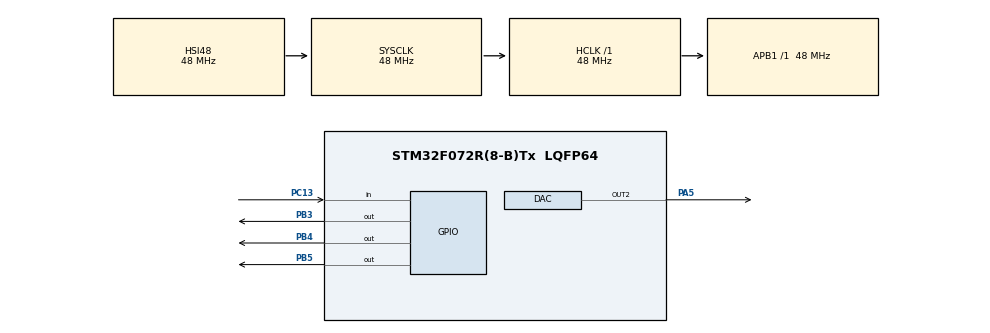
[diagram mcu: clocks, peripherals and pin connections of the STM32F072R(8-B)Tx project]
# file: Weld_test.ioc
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Mcu.Family=STM32F0
Mcu.Name=STM32F072R(8-B)Tx
Mcu.Package=LQFP64
NVIC.TIM6_DAC_IRQn=true\:0\:0\:false\:false\:true\:true\:true\:true
PA5.Signal=COMP_DAC2_group
PB3.Signal=GPIO_Output
PB4.Signal=GPIO_Output
PB5.Signal=GPIO_Output
PC13.Signal=GPIO_Input
ProjectManager.HeapSize=0x200
ProjectManager.StackSize=0x400
ProjectManager.TargetToolchain=STM32CubeIDE
RCC.AHBFreq_Value=48000000
RCC.APB1Freq_Value=48000000
RCC.APB1TimFreq_Value=48000000
RCC.HCLKFreq_Value=48000000
RCC.SYSCLKFreq_VALUE=48000000
RCC.SYSCLKSource=RCC_SYSCLKSOURCE_HSI48
SH.COMP_DAC2_group.0=DAC_OUT2,DAC_OUT2
TIM6.Period=99
TIM6.Prescaler=47
VP_TIM6_VS_ClockSourceINT.Mode=Enable_Timer
board=custom

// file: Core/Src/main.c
/* USER CODE BEGIN Header */
/**
  ******************************************************************************
  * @file           : main.c
  * @brief          : Main program body
  ******************************************************************************
  * @attention
  *
  * Copyright (c) 2026 STMicroelectronics.
  * All rights reserved.
  *
  * This software is licensed under terms that can be found in the LICENSE file
  * in the root directory of this software component.
  * If no LICENSE file comes with this software, it is provided AS-IS.
  *
  ******************************************************************************
  */
/* USER CODE END Header */
#include "main.h"

/* USER CODE BEGIN Includes */
#include "demo_wave.h"
/* USER CODE END Includes */

DAC_HandleTypeDef hdac;

TIM_HandleTypeDef htim6;

void SystemClock_Config(void);
static void MX_GPIO_Init(void);
static void MX_DAC_Init(void);
static void MX_TIM6_Init(void);

int main(void)
{

  /* MCU Configuration--------------------------------------------------------*/

  /* Reset of all peripherals, Initializes the Flash interface and the Systick. */
  HAL_Init();

  /* Configure the system clock */
  SystemClock_Config();

  /* Initialize all configured peripherals */
  MX_GPIO_Init();
  MX_DAC_Init();
  MX_TIM6_Init();
  /* USER CODE BEGIN 2 */
demo_init();
  /* USER CODE END 2 */

  /* Infinite loop */
  while (1)
  {

    /* USER CODE BEGIN 3 */
	  demo_poll();
  }
  /* USER CODE END 3 */
}

void SystemClock_Config(void)
{
  RCC_OscInitTypeDef RCC_OscInitStruct = {0};
  RCC_ClkInitTypeDef RCC_ClkInitStruct = {0};

  /** Initializes the RCC Oscillators according to the specified parameters
  * in the RCC_OscInitTypeDef structure.
  */
  RCC_OscInitStruct.OscillatorType = RCC_OSCILLATORTYPE_HSI48;
  RCC_OscInitStruct.HSI48State = RCC_HSI48_ON;
  RCC_OscInitStruct.PLL.PLLState = RCC_PLL_NONE;
  if (HAL_RCC_OscConfig(&RCC_OscInitStruct) != HAL_OK)
  {
    Error_Handler();
  }

  /** Initializes the CPU, AHB and APB buses clocks
  */
  RCC_ClkInitStruct.ClockType = RCC_CLOCKTYPE_HCLK|RCC_CLOCKTYPE_SYSCLK
                              |RCC_CLOCKTYPE_PCLK1;
  RCC_ClkInitStruct.SYSCLKSource = RCC_SYSCLKSOURCE_HSI48;
  RCC_ClkInitStruct.AHBCLKDivider = RCC_SYSCLK_DIV1;
  RCC_ClkInitStruct.APB1CLKDivider = RCC_HCLK_DIV1;

  if (HAL_RCC_ClockConfig(&RCC_ClkInitStruct, FLASH_LATENCY_1) != HAL_OK)
  {
    Error_Handler();
  }
}

static void MX_DAC_Init(void)
{

  DAC_ChannelConfTypeDef sConfig = {0};

  /** DAC Initialization
  */
  hdac.Instance = DAC;
  if (HAL_DAC_Init(&hdac) != HAL_OK)
  {
    Error_Handler();
  }

  /** DAC channel OUT2 config
  */
  sConfig.DAC_Trigger = DAC_TRIGGER_NONE;
  sConfig.DAC_OutputBuffer = DAC_OUTPUTBUFFER_ENABLE;
  if (HAL_DAC_ConfigChannel(&hdac, &sConfig, DAC_CHANNEL_2) != HAL_OK)
  {
    Error_Handler();
  }

}

static void MX_TIM6_Init(void)
{

  TIM_MasterConfigTypeDef sMasterConfig = {0};

  htim6.Instance = TIM6;
  htim6.Init.Prescaler = 47;
  htim6.Init.CounterMode = TIM_COUNTERMODE_UP;
  htim6.Init.Period = 99;
  htim6.Init.AutoReloadPreload = TIM_AUTORELOAD_PRELOAD_DISABLE;
  if (HAL_TIM_Base_Init(&htim6) != HAL_OK)
  {
    Error_Handler();
  }
  sMasterConfig.MasterOutputTrigger = TIM_TRGO_RESET;
  sMasterConfig.MasterSlaveMode = TIM_MASTERSLAVEMODE_DISABLE;
  if (HAL_TIMEx_MasterConfigSynchronization(&htim6, &sMasterConfig) != HAL_OK)
  {
    Error_Handler();
  }

}

static void MX_GPIO_Init(void)
{
  GPIO_InitTypeDef GPIO_InitStruct = {0};

  /* GPIO Ports Clock Enable */
  __HAL_RCC_GPIOC_CLK_ENABLE();
  __HAL_RCC_GPIOA_CLK_ENABLE();
  __HAL_RCC_GPIOB_CLK_ENABLE();

  /*Configure GPIO pin Output Level */
  HAL_GPIO_WritePin(GPIOB, GPIO_PIN_3|GPIO_PIN_4|GPIO_PIN_5, GPIO_PIN_RESET);

  /*Configure GPIO pin : PC13 */
  GPIO_InitStruct.Pin = GPIO_PIN_13;
  GPIO_InitStruct.Mode = GPIO_MODE_INPUT;
  GPIO_InitStruct.Pull = GPIO_NOPULL;
  HAL_GPIO_Init(GPIOC, &GPIO_InitStruct);

  /*Configure GPIO pins : PB3 PB4 PB5 */
  GPIO_InitStruct.Pin = GPIO_PIN_3|GPIO_PIN_4|GPIO_PIN_5;
  GPIO_InitStruct.Mode = GPIO_MODE_OUTPUT_PP;
  GPIO_InitStruct.Pull = GPIO_NOPULL;
  GPIO_InitStruct.Speed = GPIO_SPEED_FREQ_LOW;
  HAL_GPIO_Init(GPIOB, &GPIO_InitStruct);

}

void Error_Handler(void)
{
  __disable_irq();
  while (1)
  {
  }
}
